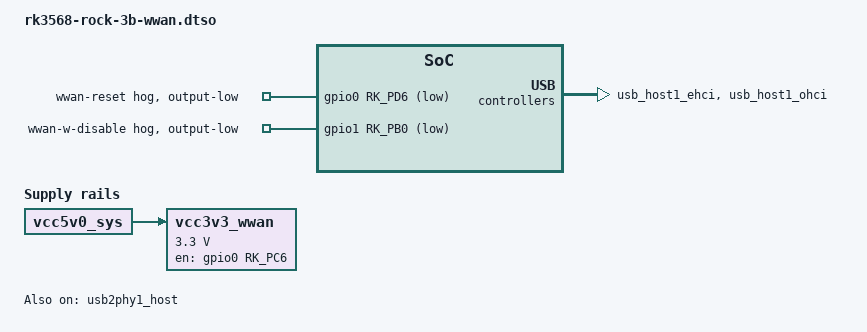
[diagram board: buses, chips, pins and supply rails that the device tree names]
// SPDX-License-Identifier: (GPL-2.0+ OR MIT)
/*
 * Device tree overlay for a WWAN module in the M.2 B-key slot
 * of the Radxa ROCK 3B.
 */

/dts-v1/;
/plugin/;

#include <dt-bindings/gpio/gpio.h>
#include <dt-bindings/pinctrl/rockchip.h>

&{/} {
	vcc3v3_wwan: regulator-3v3-vcc-wwan {
		compatible = "regulator-fixed";
		enable-active-high;
		gpios = <&gpio0 RK_PC6 GPIO_ACTIVE_HIGH>;
		pinctrl-names = "default";
		pinctrl-0 = <&wwan_pwren_h>;
		regulator-name = "vcc3v3_wwan";
		regulator-always-on;
		regulator-boot-on;
		regulator-min-microvolt = <3300000>;
		regulator-max-microvolt = <3300000>;
		vin-supply = <&vcc5v0_sys>;
	};
};

&gpio0 {
	wwan-reset-hog {
		gpio-hog;
		gpios = <RK_PD6 GPIO_ACTIVE_LOW>;
		output-low;
		line-name = "wwan-reset";
	};
};

&gpio1 {
	wwan-disable-hog {
		gpio-hog;
		gpios = <RK_PB0 GPIO_ACTIVE_LOW>;
		output-low;
		line-name = "wwan-w-disable";
	};
};

&pinctrl {
	wwan {
		wwan_pwren_h: wwan-pwren-h {
			rockchip,pins = <0 RK_PC6 RK_FUNC_GPIO &pcfg_pull_none>;
		};
	};
};

&usb_host1_ehci {
	status = "okay";
};

&usb_host1_ohci {
	status = "okay";
};

&usb2phy1_host {
	status = "okay";
};
